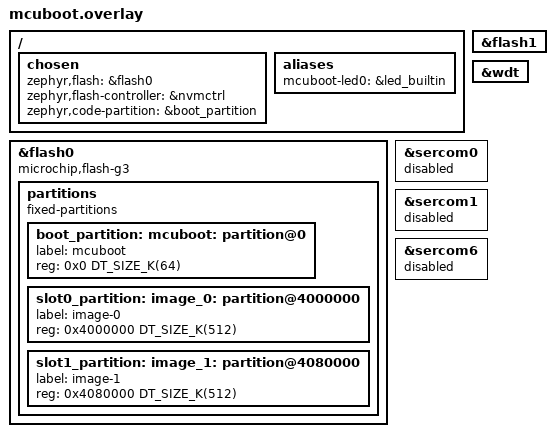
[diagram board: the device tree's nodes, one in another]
/*
 * Copyright (c) Arduino s.r.l. and/or its affiliated companies
 * SPDX-License-Identifier: Apache-2.0
 *
 * MCUboot overlay: MCUboot in BFM, USB DFU recovery. Self-contained (no
 * variant overlay, no --shield). Partitions live under flash0 (not flash1)
 * because MCUboot computes chainload addresses relative to zephyr,flash base.
 * Loader keeps its own flash1-based view — only absolute addresses must agree.
 */

/ {
	chosen {
		zephyr,flash = &flash0;
		zephyr,flash-controller = &nvmctrl;
		/* Applied after MCUboot's app.overlay, so this choice wins. */
		zephyr,code-partition = &boot_partition;
	};

	aliases {
		/* On while waiting in USB DFU (CONFIG_MCUBOOT_INDICATION_LED). */
		mcuboot-led0 = &led_builtin;
	};
};

/* Retained RAM for double tap and boot mode, shared with the loader/sketch. */
#include "retained_mem.dtsi"

/* Restore flash0 as the soc-nv-flash instance (board dtsi deletes it for the
 * loader). Partitions use child offsets: 0x4000000 == PFM 0x0C000000. */
&flash0 {
	compatible = "microchip,flash-g3", "soc-nv-flash";

	partitions {
		compatible = "fixed-partitions";
		#address-cells = <1>;
		#size-cells = <1>;

		/* Active BFM Dual-Boot slot. Spare at 0x10000 not declared. */
		boot_partition: mcuboot: partition@0 {
			label = "mcuboot";
			reg = <0x0 DT_SIZE_K(64)>;
		};

		/* 0x4000000 == PFM 0x0C000000. Loader + sketch, one signed image. */
		slot0_partition: image_0: partition@4000000 {
			label = "image-0";
			reg = <0x4000000 DT_SIZE_K(512)>;
		};

		/* DFU staging slot, copied over slot0 (overwrite-only). */
		slot1_partition: image_1: partition@4080000 {
			label = "image-1";
			reg = <0x4080000 DT_SIZE_K(512)>;
		};
	};
};

/* PFM addressed through flash0 — flash1 gives up partitions + compatible. */
&flash1 {
	/delete-node/ partitions;
	/delete-property/ compatible;
};

&wdt {
	status = "okay";
};

/* SERCOM UARTs unused (no console). Disabled here because the
 * Kconfig is promptless. Re-enable sercom6 if turning on CONSOLE for debug. */
&sercom0 { status = "disabled"; };
&sercom1 { status = "disabled"; };
&sercom6 { status = "disabled"; };
